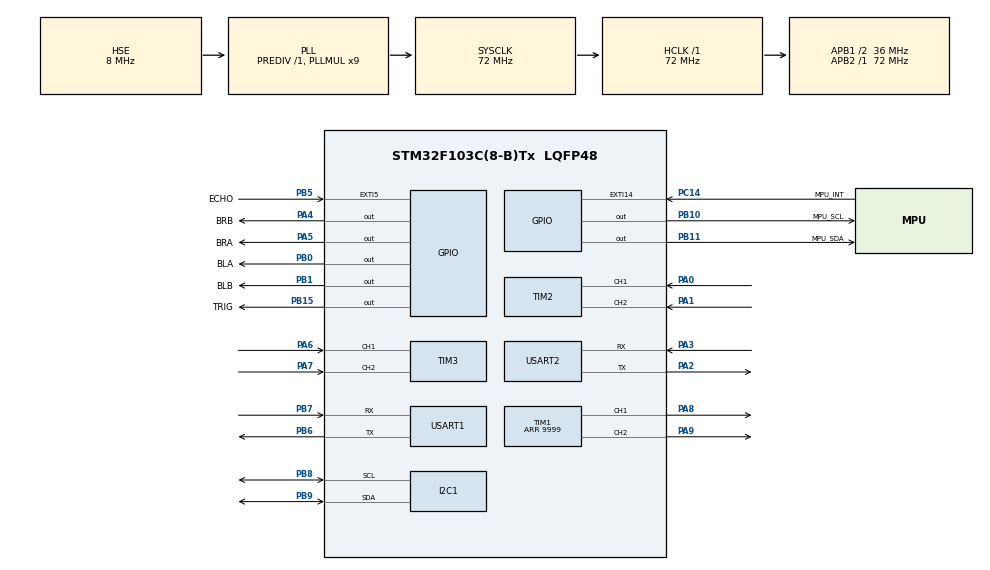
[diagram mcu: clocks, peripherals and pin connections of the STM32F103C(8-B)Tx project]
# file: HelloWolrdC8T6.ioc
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Dma.I2C1_RX.3.Direction=DMA_PERIPH_TO_MEMORY
Dma.I2C1_RX.3.Instance=DMA1_Channel7
Dma.I2C1_RX.3.MemDataAlignment=DMA_MDATAALIGN_BYTE
Dma.I2C1_RX.3.MemInc=DMA_MINC_ENABLE
Dma.I2C1_RX.3.Mode=DMA_NORMAL
Dma.I2C1_RX.3.PeriphDataAlignment=DMA_PDATAALIGN_BYTE
Dma.I2C1_RX.3.PeriphInc=DMA_PINC_DISABLE
Dma.I2C1_RX.3.Priority=DMA_PRIORITY_LOW
Dma.I2C1_TX.2.Direction=DMA_MEMORY_TO_PERIPH
Dma.I2C1_TX.2.Instance=DMA1_Channel6
Dma.I2C1_TX.2.MemDataAlignment=DMA_MDATAALIGN_BYTE
Dma.I2C1_TX.2.MemInc=DMA_MINC_ENABLE
Dma.I2C1_TX.2.Mode=DMA_NORMAL
Dma.I2C1_TX.2.PeriphDataAlignment=DMA_PDATAALIGN_BYTE
Dma.I2C1_TX.2.PeriphInc=DMA_PINC_DISABLE
Dma.I2C1_TX.2.Priority=DMA_PRIORITY_LOW
Dma.Request0=USART1_RX
Dma.Request1=USART1_TX
Dma.Request2=I2C1_TX
Dma.Request3=I2C1_RX
Dma.USART1_RX.0.Direction=DMA_PERIPH_TO_MEMORY
Dma.USART1_RX.0.Instance=DMA1_Channel5
Dma.USART1_RX.0.MemDataAlignment=DMA_MDATAALIGN_BYTE
Dma.USART1_RX.0.MemInc=DMA_MINC_ENABLE
Dma.USART1_RX.0.Mode=DMA_CIRCULAR
Dma.USART1_RX.0.PeriphDataAlignment=DMA_PDATAALIGN_BYTE
Dma.USART1_RX.0.PeriphInc=DMA_PINC_DISABLE
Dma.USART1_RX.0.Priority=DMA_PRIORITY_LOW
Dma.USART1_TX.1.Direction=DMA_MEMORY_TO_PERIPH
Dma.USART1_TX.1.Instance=DMA1_Channel4
Dma.USART1_TX.1.MemDataAlignment=DMA_MDATAALIGN_BYTE
Dma.USART1_TX.1.MemInc=DMA_MINC_ENABLE
Dma.USART1_TX.1.Mode=DMA_NORMAL
Dma.USART1_TX.1.PeriphDataAlignment=DMA_PDATAALIGN_BYTE
Dma.USART1_TX.1.PeriphInc=DMA_PINC_DISABLE
Dma.USART1_TX.1.Priority=DMA_PRIORITY_LOW
I2C1.I2C_Mode=I2C_Fast
Mcu.Family=STM32F1
Mcu.Name=STM32F103C(8-B)Tx
Mcu.Package=LQFP48
NVIC.DMA1_Channel4_IRQn=true\:14\:0\:true\:false\:true\:false\:true\:true
NVIC.DMA1_Channel5_IRQn=true\:14\:0\:true\:true\:true\:2\:false\:true\:true
NVIC.DMA1_Channel6_IRQn=true\:14\:0\:true\:true\:true\:3\:false\:true\:true
NVIC.DMA1_Channel7_IRQn=true\:14\:0\:true\:false\:true\:false\:true\:true
NVIC.EXTI15_10_IRQn=true\:0\:0\:false\:true\:true\:4\:true\:true\:true
NVIC.EXTI9_5_IRQn=true\:3\:0\:true\:true\:true\:5\:true\:true\:true
NVIC.I2C1_EV_IRQn=true\:0\:0\:true\:false\:true\:true\:true\:true
NVIC.PriorityGroup=NVIC_PRIORITYGROUP_4
NVIC.TIM2_IRQn=true\:2\:0\:true\:true\:true\:8\:true\:true\:true
NVIC.TIM3_IRQn=true\:2\:0\:true\:true\:true\:7\:true\:true\:true
NVIC.USART1_IRQn=true\:14\:0\:true\:true\:true\:1\:true\:true\:true
PA0-WKUP.Signal=S_TIM2_CH1_ETR
PA1.Signal=S_TIM2_CH2
PA13.Mode=Serial_Wire
PA13.Signal=SYS_JTMS-SWDIO
PA14.Mode=Serial_Wire
PA14.Signal=SYS_JTCK-SWCLK
PA2.Mode=Asynchronous
PA2.Signal=USART2_TX
PA3.Mode=Asynchronous
PA3.Signal=USART2_RX
PA4.GPIO_Label=BRB
PA4.Signal=GPIO_Output
PA5.GPIO_Label=BRA
PA5.Signal=GPIO_Output
PA6.Signal=S_TIM3_CH1
PA7.Signal=S_TIM3_CH2
PA8.Signal=S_TIM1_CH1
PA9.Signal=S_TIM1_CH2
PB0.GPIO_Label=BLA
PB0.Signal=GPIO_Output
PB1.GPIO_Label=BLB
PB1.Signal=GPIO_Output
PB10.GPIO_Label=MPU_SCL
PB10.GPIO_PuPd=GPIO_PULLUP
PB10.GPIO_Speed=GPIO_SPEED_FREQ_HIGH
PB10.Signal=GPIO_Output
PB11.GPIO_Label=MPU_SDA
PB11.GPIO_PuPd=GPIO_PULLUP
PB11.GPIO_Speed=GPIO_SPEED_FREQ_HIGH
PB11.Signal=GPIO_Output
PB15.GPIO_Label=TRIG
PB15.GPIO_Speed=GPIO_SPEED_FREQ_HIGH
PB15.Signal=GPIO_Output
PB5.GPIO_Label=ECHO
PB5.GPIO_ModeDefaultEXTI=GPIO_MODE_IT_RISING_FALLING
PB5.Signal=GPXTI5
PB6.Mode=Asynchronous
PB6.Signal=USART1_TX
PB7.Mode=Asynchronous
PB7.Signal=USART1_RX
PB8.Mode=I2C
PB8.Signal=I2C1_SCL
PB9.Mode=I2C
PB9.Signal=I2C1_SDA
PC14-OSC32_IN.GPIO_Label=MPU_INT
PC14-OSC32_IN.GPIO_ModeDefaultEXTI=GPIO_MODE_IT_FALLING
PC14-OSC32_IN.Signal=GPXTI14
PD0-OSC_IN.Mode=HSE-External-Oscillator
PD0-OSC_IN.Signal=RCC_OSC_IN
PD1-OSC_OUT.Mode=HSE-External-Oscillator
PD1-OSC_OUT.Signal=RCC_OSC_OUT
ProjectManager.HeapSize=0x200
ProjectManager.StackSize=0x400
ProjectManager.TargetToolchain=MDK-ARM V5.32
RCC.AHBFreq_Value=72000000
RCC.APB1CLKDivider=RCC_HCLK_DIV2
RCC.APB1Freq_Value=36000000
RCC.APB1TimFreq_Value=72000000
RCC.APB2Freq_Value=72000000
RCC.APB2TimFreq_Value=72000000
RCC.HCLKFreq_Value=72000000
RCC.PLLMUL=RCC_PLL_MUL9
RCC.PLLSourceVirtual=RCC_PLLSOURCE_HSE
RCC.SYSCLKFreq_VALUE=72000000
RCC.SYSCLKSource=RCC_SYSCLKSOURCE_PLLCLK
RCC.USBFreq_Value=72000000
SH.S_TIM1_CH1.0=TIM1_CH1,PWM Generation1 CH1
SH.S_TIM1_CH2.0=TIM1_CH2,PWM Generation2 CH2
SH.S_TIM2_CH1_ETR.0=TIM2_CH1,Encoder_Interface
SH.S_TIM2_CH2.0=TIM2_CH2,Encoder_Interface
SH.S_TIM3_CH1.0=TIM3_CH1,Encoder_Interface
SH.S_TIM3_CH2.0=TIM3_CH2,Encoder_Interface
TIM1.AutoReloadPreload=TIM_AUTORELOAD_PRELOAD_ENABLE
TIM1.Channel-PWM\ Generation1\ CH1=TIM_CHANNEL_1
TIM1.Channel-PWM\ Generation2\ CH2=TIM_CHANNEL_2
TIM1.Period=9999
TIM2.EncoderMode=TIM_ENCODERMODE_TI12
TIM2.IC1Polarity=TIM_ICPOLARITY_FALLING
TIM2.IC2Polarity=TIM_ICPOLARITY_FALLING
TIM3.AutoReloadPreload=TIM_AUTORELOAD_PRELOAD_ENABLE
TIM3.CounterMode=TIM_COUNTERMODE_UP
TIM3.EncoderMode=TIM_ENCODERMODE_TI12
TIM3.IC1Polarity=TIM_ICPOLARITY_RISING
TIM3.IC2Filter=10
TIM3.IC2Polarity=TIM_ICPOLARITY_RISING
TIM4.CounterMode=TIM_COUNTERMODE_UP
TIM4.Period=65535
TIM4.Prescaler=71
USART1.VirtualMode=VM_ASYNC
USART2.VirtualMode=VM_ASYNC
VP_TIM1_VS_ClockSourceINT.Mode=Internal
VP_TIM4_VS_ClockSourceINT.Mode=Internal
board=custom

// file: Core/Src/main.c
/* USER CODE BEGIN Header */
/**
  ******************************************************************************
  * @file           : main.c
  * @brief          : Main program body
  ******************************************************************************
  * @attention
  *
  * Copyright (c) 2022 STMicroelectronics.
  * All rights reserved.
  *
  * This software is licensed under terms that can be found in the LICENSE file
  * in the root directory of this software component.
  * If no LICENSE file comes with this software, it is provided AS-IS.
  *
  ******************************************************************************
  */
/* USER CODE END Header */
#include "main.h"
#include "dma.h"
#include "i2c.h"
#include "tim.h"
#include "usart.h"
#include "gpio.h"

/* USER CODE BEGIN Includes */
#include"run_main.h"
/* USER CODE END Includes */

void SystemClock_Config(void);
static void MX_NVIC_Init(void);

int main(void)
{

  /* MCU Configuration--------------------------------------------------------*/

  /* Reset of all peripherals, Initializes the Flash interface and the Systick. */
  HAL_Init();

  /* Configure the system clock */
  SystemClock_Config();

  /* Initialize all configured peripherals */
  MX_GPIO_Init();
  MX_DMA_Init();
  MX_I2C1_Init();
  MX_USART1_UART_Init();
  MX_USART2_UART_Init();
  MX_TIM2_Init();
  MX_TIM3_Init();
  MX_TIM1_Init();
  MX_TIM4_Init();

  /* Initialize interrupts */
  MX_NVIC_Init();

  /* Infinite loop */
  /* USER CODE BEGIN WHILE */
  while (1)
  {
		run_main();
    /* USER CODE END WHILE */

  }
}

void SystemClock_Config(void)
{
  RCC_OscInitTypeDef RCC_OscInitStruct = {0};
  RCC_ClkInitTypeDef RCC_ClkInitStruct = {0};

  /** Initializes the RCC Oscillators according to the specified parameters
  * in the RCC_OscInitTypeDef structure.
  */
  RCC_OscInitStruct.OscillatorType = RCC_OSCILLATORTYPE_HSE;
  RCC_OscInitStruct.HSEState = RCC_HSE_ON;
  RCC_OscInitStruct.HSEPredivValue = RCC_HSE_PREDIV_DIV1;
  RCC_OscInitStruct.HSIState = RCC_HSI_ON;
  RCC_OscInitStruct.PLL.PLLState = RCC_PLL_ON;
  RCC_OscInitStruct.PLL.PLLSource = RCC_PLLSOURCE_HSE;
  RCC_OscInitStruct.PLL.PLLMUL = RCC_PLL_MUL9;
  if (HAL_RCC_OscConfig(&RCC_OscInitStruct) != HAL_OK)
  {
    Error_Handler();
  }

  /** Initializes the CPU, AHB and APB buses clocks
  */
  RCC_ClkInitStruct.ClockType = RCC_CLOCKTYPE_HCLK|RCC_CLOCKTYPE_SYSCLK
                              |RCC_CLOCKTYPE_PCLK1|RCC_CLOCKTYPE_PCLK2;
  RCC_ClkInitStruct.SYSCLKSource = RCC_SYSCLKSOURCE_PLLCLK;
  RCC_ClkInitStruct.AHBCLKDivider = RCC_SYSCLK_DIV1;
  RCC_ClkInitStruct.APB1CLKDivider = RCC_HCLK_DIV2;
  RCC_ClkInitStruct.APB2CLKDivider = RCC_HCLK_DIV1;

  if (HAL_RCC_ClockConfig(&RCC_ClkInitStruct, FLASH_LATENCY_2) != HAL_OK)
  {
    Error_Handler();
  }
}

/**
  * @brief NVIC Configuration.
  * @retval None
  */
static void MX_NVIC_Init(void)
{
  /* USART1_IRQn interrupt configuration */
  HAL_NVIC_SetPriority(USART1_IRQn, 14, 0);
  HAL_NVIC_EnableIRQ(USART1_IRQn);
  /* DMA1_Channel5_IRQn interrupt configuration */
  HAL_NVIC_SetPriority(DMA1_Channel5_IRQn, 14, 0);
  HAL_NVIC_EnableIRQ(DMA1_Channel5_IRQn);
  /* DMA1_Channel6_IRQn interrupt configuration */
  HAL_NVIC_SetPriority(DMA1_Channel6_IRQn, 14, 0);
  HAL_NVIC_EnableIRQ(DMA1_Channel6_IRQn);
  /* EXTI15_10_IRQn interrupt configuration */
  HAL_NVIC_SetPriority(EXTI15_10_IRQn, 0, 0);
  HAL_NVIC_EnableIRQ(EXTI15_10_IRQn);
  /* EXTI9_5_IRQn interrupt configuration */
  HAL_NVIC_SetPriority(EXTI9_5_IRQn, 3, 0);
  HAL_NVIC_EnableIRQ(EXTI9_5_IRQn);
  /* TIM3_IRQn interrupt configuration */
  HAL_NVIC_SetPriority(TIM3_IRQn, 2, 0);
  HAL_NVIC_EnableIRQ(TIM3_IRQn);
  /* TIM2_IRQn interrupt configuration */
  HAL_NVIC_SetPriority(TIM2_IRQn, 2, 0);
  HAL_NVIC_EnableIRQ(TIM2_IRQn);
}

void Error_Handler(void)
{
  __disable_irq();
  while (1)
  {
  }
}
